AUTOSAR XML (schema 4.0)
standard types defined: float32, float64, sint16, sint32, sint8, uint16, uint32, uint8, void, boolean
package /ImplDataTypes
  impl type MultiStateBtnType: implementation-data-type=uint8, type-emitter=RTE
  impl type StepMotorStepType: implementation-data-type=uint8, type-emitter=RTE
package /MappingSets
  data type mapping set MappingSet
package /PortInterfaces/ClientServer
  client server interface CsIf_StepMotor
    operation Opr_Move
      arg Arg_step: type=StepMotorStepType, direction=IN
package /PortInterfaces/SenderReceiver
  sender receiver interface SrIf_SeatCtrlBtns
    data DE_HeightBtnState: type=MultiStateBtnType
    data DE_InclineBtnState: type=MultiStateBtnType
    data DE_SlideBtnState: type=MultiStateBtnType
  sender receiver interface SrIf_SeatCtrlData
    data DE_Height: type=uint8
    data DE_Incline: type=uint8
    data DE_Slide: type=uint8
package /SoftwareComponents
  6 x swc implementation, all with programming-language=C, sw-version=1.0.0, vendor-id=255:
    Impl_SWC_ECU1: behavior=Ibhv_SWC_ECU1
      code-descriptors:
        code Code: artifact-descriptors=autosar-engineering-object={short-label=SWC.c, category=SWSRC}
      resource consumption ResourceConsumption
    Impl_SWC_HMI: behavior=Ibhv_SWC_HMI
      code-descriptors:
        code Code: artifact-descriptors=autosar-engineering-object={short-label=SWC.c, category=SWSRC}
      resource consumption ResourceConsumption
    Impl_SWC_HeightMotor: behavior=Ibhv_SWC_HeightMotor
      code-descriptors:
        code Code: artifact-descriptors=autosar-engineering-object={short-label=SWC.c, category=SWSRC}
      resource consumption ResourceConsumption
    Impl_SWC_InclineMotor: behavior=Ibhv_SWC_InclineMotor
      code-descriptors:
        code Code: artifact-descriptors=autosar-engineering-object={short-label=SWC.c, category=SWSRC}
      resource consumption ResourceConsumption
    Impl_SWC_SeatMgr: behavior=Ibhv_SWC_SeatMgr
      code-descriptors:
        code Code: artifact-descriptors=autosar-engineering-object={short-label=SWC.c, category=SWSRC}
      resource consumption ResourceConsumption
    Impl_SWC_SlideMotor: behavior=Ibhv_SWC_SlideMotor
      code-descriptors:
        code Code: artifact-descriptors=autosar-engineering-object={short-label=SWC.c, category=SWSRC}
      resource consumption ResourceConsumption
  application sw component type SWC_ECU1
    provide port pp_SeatCtrlData: provided-interface=SrIf_SeatCtrlData
    behavior Ibhv_SWC_ECU1: data-type-mapping=MappingSet, handle-termination-and-restart=NO-SUPPORT
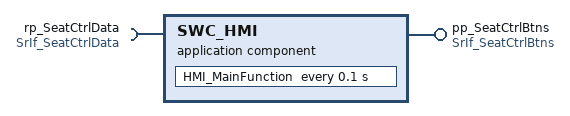
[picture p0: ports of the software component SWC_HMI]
  application sw component type SWC_HMI
    provide port pp_SeatCtrlBtns: provided-interface=SrIf_SeatCtrlBtns
    require port rp_SeatCtrlData: required-interface=SrIf_SeatCtrlData
    behavior Ibhv_SWC_HMI: data-type-mapping=MappingSet, handle-termination-and-restart=NO-SUPPORT
      timing event TE_HMI_MainFunction_100ms: start-on-event=HMI_MainFunction, period=0.1
      runnable HMI_MainFunction
        data-receive-point-by-arguments:
          access DRP_rp_SeatCtrlData_DE_Height: accessed-variable=rp_SeatCtrlData.DE_Height
          access DRP_rp_SeatCtrlData_DE_Incline: accessed-variable=rp_SeatCtrlData.DE_Incline
          access DRP_rp_SeatCtrlData_DE_Slide: accessed-variable=rp_SeatCtrlData.DE_Slide
        data-send-points:
          access DSP_pp_SeatCtrlBtns_DE_HeightBtnState: accessed-variable=pp_SeatCtrlBtns.DE_HeightBtnState
          access DSP_pp_SeatCtrlBtns_DE_InclineBtnState: accessed-variable=pp_SeatCtrlBtns.DE_InclineBtnState
          access DSP_pp_SeatCtrlBtns_DE_SlideBtnState: accessed-variable=pp_SeatCtrlBtns.DE_SlideBtnState
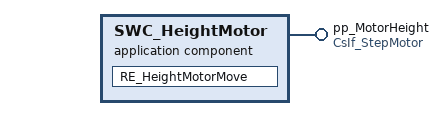
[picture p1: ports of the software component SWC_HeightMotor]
  application sw component type SWC_HeightMotor
    provide port pp_MotorHeight: provided-interface=CsIf_StepMotor
    behavior Ibhv_SWC_HeightMotor: data-type-mapping=MappingSet, handle-termination-and-restart=NO-SUPPORT
      operation invoked event OIE_pp_MotorHeight_Opr_Move: start-on-event=RE_HeightMotorMove, operation=pp_MotorHeight.Opr_Move
      runnable RE_HeightMotorMove
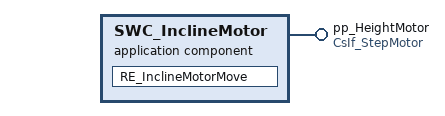
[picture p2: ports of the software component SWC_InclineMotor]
  application sw component type SWC_InclineMotor
    provide port pp_HeightMotor: provided-interface=CsIf_StepMotor
    behavior Ibhv_SWC_InclineMotor: data-type-mapping=MappingSet, handle-termination-and-restart=NO-SUPPORT
      operation invoked event OIE_pp_HeightMotor_Opr_Move: start-on-event=RE_InclineMotorMove, operation=pp_HeightMotor.Opr_Move
      runnable RE_InclineMotorMove
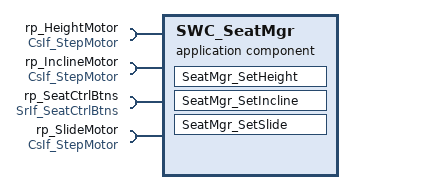
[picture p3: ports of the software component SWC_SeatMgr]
  application sw component type SWC_SeatMgr
    4 x require port:
      rp_HeightMotor: required-interface=CsIf_StepMotor
      rp_InclineMotor: required-interface=CsIf_StepMotor
      rp_SeatCtrlBtns: required-interface=SrIf_SeatCtrlBtns
      rp_SlideMotor: required-interface=CsIf_StepMotor
    behavior Ibhv_SWC_SeatMgr: data-type-mapping=MappingSet, handle-termination-and-restart=NO-SUPPORT
      data received event DRE_rp_SeatCtrlBtns_DE_HeightBtnState: start-on-event=SeatMgr_SetHeight, data=rp_SeatCtrlBtns.DE_HeightBtnState
      data received event DRE_rp_SeatCtrlBtns_DE_InclineBtnState: start-on-event=SeatMgr_SetIncline, data=rp_SeatCtrlBtns.DE_InclineBtnState
      data received event DRE_rp_SeatCtrlBtns_DE_SlideBtnState: start-on-event=SeatMgr_SetSlide, data=rp_SeatCtrlBtns.DE_SlideBtnState
      runnable SeatMgr_SetHeight
        data-receive-point-by-arguments:
          access DRP_rp_SeatCtrlBtns_DE_HeightBtnState: accessed-variable=rp_SeatCtrlBtns.DE_HeightBtnState
        sync call SCP_rp_HeightMotor_Opr_Move: operation=rp_HeightMotor.Opr_Move, timeout=0.0
      runnable SeatMgr_SetIncline
        data-receive-point-by-arguments:
          access DRP_rp_SeatCtrlBtns_DE_InclineBtnState: accessed-variable=rp_SeatCtrlBtns.DE_InclineBtnState
        sync call SCP_rp_InclineMotor_Opr_Move: operation=rp_InclineMotor.Opr_Move, timeout=0.0
      runnable SeatMgr_SetSlide
        data-receive-point-by-arguments:
          access DRP_rp_SeatCtrlBtns_DE_SlideBtnState: accessed-variable=rp_SeatCtrlBtns.DE_SlideBtnState
        sync call SCP_rp_SlideMotor_Opr_Move: operation=rp_SlideMotor.Opr_Move, timeout=0.0
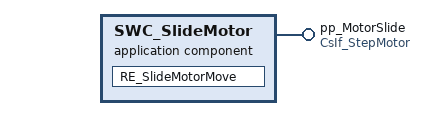
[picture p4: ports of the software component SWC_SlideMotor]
  application sw component type SWC_SlideMotor
    provide port pp_MotorSlide: provided-interface=CsIf_StepMotor
    behavior Ibhv_SWC_SlideMotor: data-type-mapping=MappingSet, handle-termination-and-restart=NO-SUPPORT
      operation invoked event OIE_pp_MotorSlide_Opr_Move: start-on-event=RE_SlideMotorMove, operation=pp_MotorSlide.Opr_Move
      runnable RE_SlideMotorMove
package /Compositions
  composition sw component type SeatCtrlComposition
    component SWC_HMI: type=SWC_HMI
    component SWC_SeatMgr: type=SWC_SeatMgr
